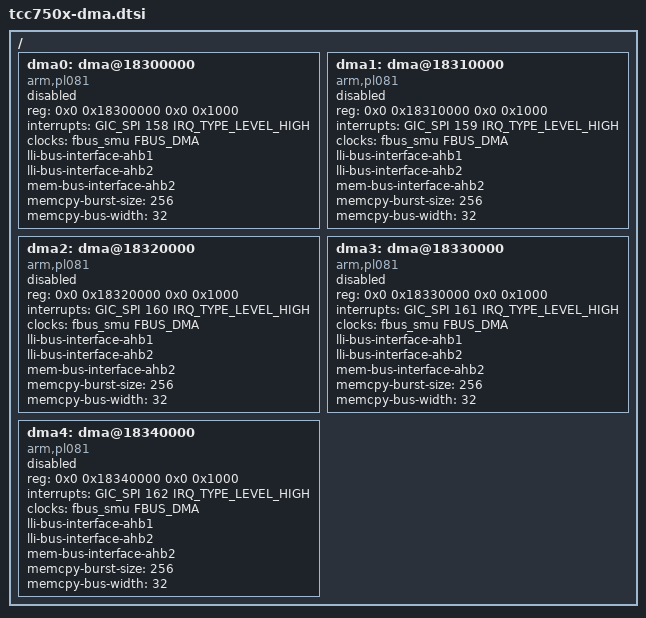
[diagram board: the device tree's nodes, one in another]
// SPDX-License-Identifier: (GPL-2.0-or-later OR MIT)
/*
 * Copyright (C) 2023 Telechips Inc.
 */

#include <dt-bindings/clock/telechips,tcc750x-clks.h>
#include <dt-bindings/interrupt-controller/arm-gic.h>

/ {
	dma0: dma@18300000 {
		compatible = "arm,pl081", "arm,primecell";
		reg = <0x0 0x18300000 0x0 0x1000>;
		interrupts = <GIC_SPI 158 IRQ_TYPE_LEVEL_HIGH>;
		clocks = <&fbus_smu FBUS_DMA>;
		clock-names = "apb_pclk";
		lli-bus-interface-ahb1;
		lli-bus-interface-ahb2;
		mem-bus-interface-ahb2;
		memcpy-burst-size = <256>;
		memcpy-bus-width = <32>;
		#dma-cells = <2>;
		status = "disabled";
	};

	dma1: dma@18310000 {
		compatible = "arm,pl081", "arm,primecell";
		reg = <0x0 0x18310000 0x0 0x1000>;
		interrupts = <GIC_SPI 159 IRQ_TYPE_LEVEL_HIGH>;
		clocks = <&fbus_smu FBUS_DMA>;
		clock-names = "apb_pclk";
		lli-bus-interface-ahb1;
		lli-bus-interface-ahb2;
		mem-bus-interface-ahb2;
		memcpy-burst-size = <256>;
		memcpy-bus-width = <32>;
		#dma-cells = <2>;
		status = "disabled";
	};

	dma2: dma@18320000 {
		compatible = "arm,pl081", "arm,primecell";
		reg = <0x0 0x18320000 0x0 0x1000>;
		interrupts = <GIC_SPI 160 IRQ_TYPE_LEVEL_HIGH>;
		clocks = <&fbus_smu FBUS_DMA>;
		clock-names = "apb_pclk";
		lli-bus-interface-ahb1;
		lli-bus-interface-ahb2;
		mem-bus-interface-ahb2;
		memcpy-burst-size = <256>;
		memcpy-bus-width = <32>;
		#dma-cells = <2>;
		status = "disabled";
	};

	dma3: dma@18330000 {
		compatible = "arm,pl081", "arm,primecell";
		reg = <0x0 0x18330000 0x0 0x1000>;
		interrupts = <GIC_SPI 161 IRQ_TYPE_LEVEL_HIGH>;
		clocks = <&fbus_smu FBUS_DMA>;
		clock-names = "apb_pclk";
		lli-bus-interface-ahb1;
		lli-bus-interface-ahb2;
		mem-bus-interface-ahb2;
		memcpy-burst-size = <256>;
		memcpy-bus-width = <32>;
		#dma-cells = <2>;
		status = "disabled";
	};

	dma4: dma@18340000 {
		compatible = "arm,pl081", "arm,primecell";
		reg = <0x0 0x18340000 0x0 0x1000>;
		interrupts = <GIC_SPI 162 IRQ_TYPE_LEVEL_HIGH>;
		clocks = <&fbus_smu FBUS_DMA>;
		clock-names = "apb_pclk";
		lli-bus-interface-ahb1;
		lli-bus-interface-ahb2;
		mem-bus-interface-ahb2;
		memcpy-burst-size = <256>;
		memcpy-bus-width = <32>;
		#dma-cells = <2>;
		status = "disabled";
	};
};
